# DSPIC33FJ32GP104 register map
Vendor: Microchip
Architecture 33xxxx. Special function registers and configuration words.
Registers are 16-bit, read-write, reset 0x0 unless marked. A register's access mark holds for its fields unless they carry their own. Addresses are absolute, and some are shared; only a register's first bit layout is shown; lines under a group give offsets from that group; [hi:lo] are bit positions; {n}, {i} and the like mark numbered series; 'fields as' and 'values as' point back to an identical list; <NAME> marks a mode.

## Further device data
pins=1: MCLR; 2: PGED2/AN0/C3INB/C1INA/CTED1/CN2/RA0; 3: PGEC2/AN1/C3INA/C1INB/CTED2/CN3/RA1; 4: PGED1/AN2/C2INA/C1INC/CTCMP/RP0/CN4/RB0; 5: PGEC1/AN3/CVrefin/CVrefout/C2INB/C1IND/RP1/CN5/RB1; 6: AN4/C3INC/C2INC/RP2/CN6/RB2; 7: AN5/C3IND/C2IND/RP3/CN7/RB3; 8: Vss; 9: OSCI/CLKI/CN30/RA2; 10: OSCO/CLKO/CN29/RA3; 11: PGED3/SOSCI/RP4/CN1/RB4; 12: PGEC3/SOSCO/T1CK/CN0/RA4; 13: Vdd; 14: ASDA1/RP5/CN27/RB5; 15: ASCL1/RP6/CN24/RB6; 16: SCK1/INT0/RP7/CN23/RB7; 17: TCK/SCL1/SDO1/RP8/CN22/RB8; 18: TDO/SDA1/SDI1/RP9/CN21/RB9; 19: Vss; 20: Vcap; 21: TDI/RP10/CN16/RB10; 22: TMS/RP11/CN15/RB11; 23: RP12/CN14/RB12; 24: RP13/CN13/RB13; 25: RTCC/RP14/CN12/RB14; 26: RP15/CN11/RB15; 27: AVss; 28: AVdd, interrupts=0 INT0Interrupt — INT0 - External Interrupt 0; 1 IC1Interrupt — IC1 - Input Compare 1; 2 OC1Interrupt — OC1 - Output Compare 1; 3 T1Interrupt — T1 - Timer1; 5 IC2Interrupt — IC2 - Input Capture 2; 6 OC2Interrupt — OC2 - Output Compare 2; 7 T2Interrupt — T2 - Timer2; 8 T3Interrupt — T3 - Timer3; 9 SPI1ErrInterrupt — SPI1E - SPI1 Error; 10 SPI1Interrupt — SPI1 - SPI1 Transfer Done; 11 U1RXInterrupt — U1RX - UART1 Receiver; 12 U1TXInterrupt — U1TX - UART1 Transmitter; 13 ADC1Interrupt — ADC1 - A/D Converter 1; 16 SI2C1Interrupt — SI2C1 - I2C1 Slave Events; 17 MI2C1Interrupt — MI2C1 - I2C1 Master Events; 18 CompInterrupt — Analog Comparator Interrupt; 19 CNInterrupt — Change Notification Interrupt; 20 INT1Interrupt — INT1 - External Interrupt 1; 27 T4Interrupt — T4 - Timer4; 28 T5Interrupt — T5 - Timer5; 29 INT2Interrupt — INT2 - External Interrupt 2; 37 IC3Interrupt — Input Capture 3; 62 RTCCInterrupt — RTCC - Real-Time Clock and Calendar; 65 U1ErrInterrupt — U1E - UART1 Error; 77 CTMUInterrupt — CTMU - Interrupt

## CONFIG — Configuration words, addresses in ProgramSpace
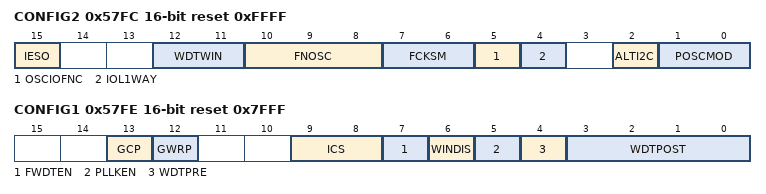
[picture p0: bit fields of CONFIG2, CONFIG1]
0x57FC CONFIG2 reset 0xFFFF
  [15] IESO — Internal External Switch Over Mode
    0=OFF (Start-up device with user-selected oscillator source); 1=ON (Start-up device with FRC, then automatically switch to user-selected oscillator source when ready)
  [12:11] WDTWIN — Watchdog Window Select
    3=Watchdog Window is 25% of WDT period; 2=Watchdog Window is 37.5% of WDT period; 1=Watchdog Window is 50% of WDT period; 0=Watchdog Window is 75% of WDT period
  [10:8] FNOSC — Oscillator Mode
    0=FRC (Internal Fast RC (FRC)); 1=FRCPLL (Internal Fast RC (FRC) w/ PLL); 2=PRI (Primary Oscillator (MS, HS, EC)); 3=PRIPLL (Primary Oscillator (MS, HS, EC) w/ PLL); 4=SOSC (Secondary Oscillator (SOSC)); 5=LPRC (Low Power RC Oscillator (LPRC)); 7=FRCDIVN (Internal Fast RC (FRC) with divide by N)
  [7:6] FCKSM — Clock Switching and Monitor
    0b1x=CSDCMD (Clock switching and Fail-Safe Clock Monitor are disabled); 1=CSECMD (Clock switching is enabled, Fail-Safe Clock Monitor is disabled); 0=CSECME (Clock switching is enabled, Fail-Safe Clock Monitor is enabled)
  [5] OSCIOFNC — Primary Oscillator Output Function
    0=ON (OSC2 pin has digital I/O function); 1=OFF (OSC2 pin has clock out function)
  [4] IOL1WAY — IOLOCK Protection
    0=OFF (Allow Multiple Re-configurations); 1=ON (Allow Only One Re-configuration)
  [2] ALTI2C ro — Alternate I2C pins
    1=OFF (I2C mapped to SDA1/SCL1); 0=ON (I2C mapped to ASDA1/ASCL1)
  [1:0] POSCMOD — Primary Oscillator Select
    3=NONE (Primary oscillator disabled); 2=HS (HS Oscillator mode selected); 1=MS (MS Oscillator mode selected); 0=EC (EC Oscillator mode selected)
0x57FE CONFIG1 reset 0x7FFF
  [13] GCP — General Segment Code Protection
    1=OFF (General Segment Code protect is disabled); 0=ON (Standard Security Code protection Enabled)
  [12] GWRP — General Code Segment Write Protect
    1=OFF (Writes to program memory are allowed); 0=ON (Writes to program memory are disabled)
  [9:8] ICS — Comm Channel Select
    3=PGD1 (Communicate on PGEC1/PGED1); 2=PGD2 (Communicate on PGEC2/PGED2); 1=PGD3 (Communicate on PGEC3/PGED3)
  [7] FWDTEN — Watchdog Timer Enable
    1=ON (Watchdog timer always enabled); 0=OFF (Watchdog timer enabled/disabled by user software)
  [6] WINDIS — Watchdog Timer Window
    1=OFF (Watchdog Timer in Non-Window mode); 0=ON (Watchdog Timer in Window mode)
  [5] PLLKEN — PLL Lock Enable
    1=ON (Clock switch to PLL source will wait until the PLL lock signal is valid.); 0=OFF (Clock switch will not wait for the PLL lock signal.)
  [4] WDTPRE — WDT Prescaler
    1=PR128 (Prescaler ratio of 1:128); 0=PR32 (Prescaler ratio of 1:32)
  [3:0] WDTPOST — Watchdog Timer Postscaler
    15=PS32768 (1:32,768); 14=PS16384 (1:16,384); 13=PS8192 (1:8,192); 12=PS4096 (1:4,096); 11=PS2048 (1:2,048); 10=PS1024 (1:1,024); 9=PS512 (1:512); 8=PS256 (1:256); 7=PS128 (1:128); 6=PS64 (1:64); 5=PS32 (1:32); 4=PS16 (1:16); 3=PS8 (1:8); 2=PS4 (1:4); 1=PS2 (1:2); 0=PS1 (1:1)
